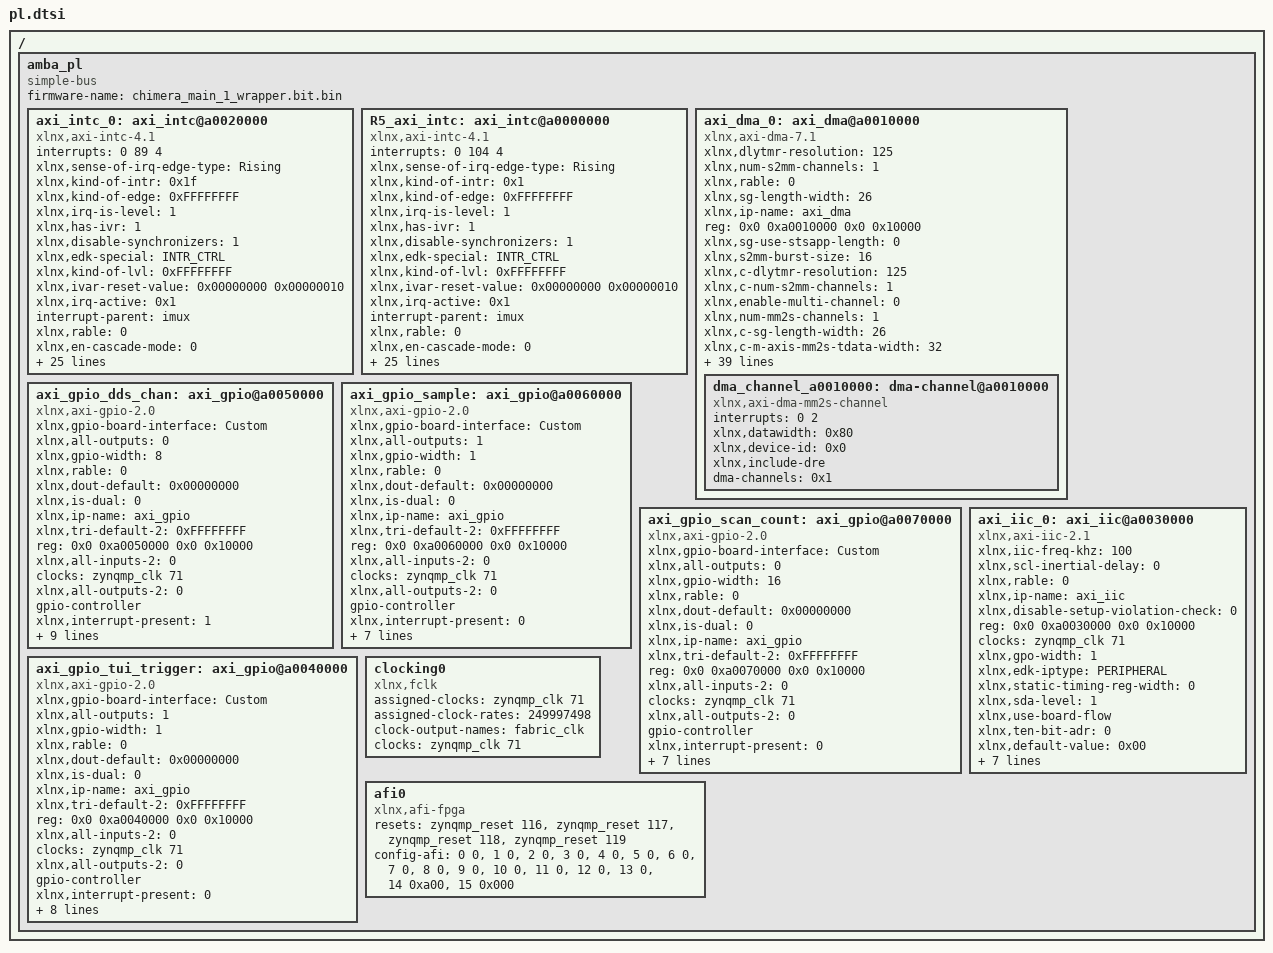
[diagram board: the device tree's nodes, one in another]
/ {
	amba_pl: amba_pl {
		ranges;
		compatible = "simple-bus";
		#address-cells = <2>;
		#size-cells = <2>;
		firmware-name = "chimera_main_1_wrapper.bit.bin";
		axi_intc_0: axi_intc@a0020000 {
			#interrupt-cells = <2>;
			interrupts = < 0 89 4 >;
			xlnx,sense-of-irq-edge-type = "Rising";
			xlnx,kind-of-intr = <0x1f>;
			xlnx,kind-of-edge = <0xFFFFFFFF>;
			xlnx,irq-is-level = <1>;
			xlnx,has-ivr = <1>;
			compatible = "xlnx,axi-intc-4.1" , "xlnx,xps-intc-1.00.a";
			xlnx,disable-synchronizers = <1>;
			xlnx,edk-special = "INTR_CTRL";
			xlnx,kind-of-lvl = <0xFFFFFFFF>;
			xlnx,ivar-reset-value = <0x00000000 0x00000010>;
			xlnx,irq-active = <0x1>;
			interrupt-parent = <&imux>;
			xlnx,rable = <0>;
			xlnx,en-cascade-mode = <0>;
			xlnx,ip-name = "axi_intc";
			xlnx,has-ilr = <0>;
			reg = <0x0 0xa0020000 0x0 0x10000>;
			xlnx,addr-width = <0x20>;
			clocks = <&zynqmp_clk 71>;
			xlnx,s-axi-aclk-freq-mhz = <0xee6a8ba>;
			xlnx,num-sw-intr = <0>;
			xlnx,irq-connection = <1>;
			xlnx,num-intr-inputs = <0x5>;
			xlnx,has-sie = <1>;
			xlnx,has-cie = <1>;
			xlnx,enable-async = <0>;
			xlnx,num-sync-ff = <2>;
			xlnx,mb-clk-not-connected = <1>;
			xlnx,has-ipr = <1>;
			xlnx,edk-iptype = "PERIPHERAL";
			xlnx,sense-of-irq-level-type = "Active_High";
			xlnx,cascade-master = <0>;
			xlnx,processor-clk-freq-mhz = <250>;
			status = "okay";
			xlnx,is-fast = <0x0>;
			clock-names = "s_axi_aclk";
			xlnx,has-fast = <0>;
			xlnx,ivar-rst-val = <0x0000000000000010>;
			interrupt-controller;
			interrupt-names = "irq";
			xlnx,async-intr = <0xFFFFFFE0>;
			xlnx,name = "axi_intc_0";
		};
		R5_axi_intc: axi_intc@a0000000 {
			#interrupt-cells = <2>;
			interrupts = < 0 104 4 >;
			xlnx,sense-of-irq-edge-type = "Rising";
			xlnx,kind-of-intr = <0x1>;
			xlnx,kind-of-edge = <0xFFFFFFFF>;
			xlnx,irq-is-level = <1>;
			xlnx,has-ivr = <1>;
			compatible = "xlnx,axi-intc-4.1" , "xlnx,xps-intc-1.00.a";
			xlnx,disable-synchronizers = <1>;
			xlnx,edk-special = "INTR_CTRL";
			xlnx,kind-of-lvl = <0xFFFFFFFF>;
			xlnx,ivar-reset-value = <0x00000000 0x00000010>;
			xlnx,irq-active = <0x1>;
			interrupt-parent = <&imux>;
			xlnx,rable = <0>;
			xlnx,en-cascade-mode = <0>;
			xlnx,ip-name = "axi_intc";
			xlnx,has-ilr = <0>;
			reg = <0x0 0xa0000000 0x0 0x10000>;
			xlnx,addr-width = <0x20>;
			clocks = <&zynqmp_clk 71>;
			xlnx,s-axi-aclk-freq-mhz = <0xee6a8ba>;
			xlnx,num-sw-intr = <0>;
			xlnx,irq-connection = <1>;
			xlnx,num-intr-inputs = <0x1>;
			xlnx,has-sie = <1>;
			xlnx,has-cie = <1>;
			xlnx,enable-async = <0>;
			xlnx,num-sync-ff = <2>;
			xlnx,mb-clk-not-connected = <1>;
			xlnx,has-ipr = <1>;
			xlnx,edk-iptype = "PERIPHERAL";
			xlnx,sense-of-irq-level-type = "Active_High";
			xlnx,cascade-master = <0>;
			xlnx,processor-clk-freq-mhz = <250>;
			status = "okay";
			xlnx,is-fast = <0x0>;
			clock-names = "s_axi_aclk";
			xlnx,has-fast = <0>;
			xlnx,ivar-rst-val = <0x0000000000000010>;
			interrupt-controller;
			interrupt-names = "irq";
			xlnx,async-intr = <0xFFFFFFFF>;
			xlnx,name = "R5_axi_intc";
		};
		axi_dma_0: axi_dma@a0010000 {
			xlnx,dlytmr-resolution = <125>;
			xlnx,num-s2mm-channels = <1>;
			xlnx,rable = <0>;
			xlnx,sg-length-width = <26>;
			xlnx,ip-name = "axi_dma";
			reg = <0x0 0xa0010000 0x0 0x10000>;
			xlnx,sg-use-stsapp-length = <0>;
			xlnx,s2mm-burst-size = <16>;
			xlnx,c-dlytmr-resolution = <125>;
			xlnx,c-num-s2mm-channels = <1>;
			xlnx,enable-multi-channel = <0>;
			xlnx,num-mm2s-channels = <1>;
			xlnx,c-sg-length-width = <26>;
			interrupt-names = "mm2s_introut";
			compatible = "xlnx,axi-dma-7.1" , "xlnx,axi-dma-1.00.a";
			xlnx,c-m-axis-mm2s-tdata-width = <32>;
			xlnx,c-sg-use-stsapp-length = <0>;
			xlnx,c-s2mm-burst-size = <16>;
			xlnx,mm2s-burst-size = <32>;
			xlnx,c-enable-multi-channel = <0>;
			xlnx,c-num-mm2s-channels = <1>;
			interrupt-parent = <&axi_intc_0>;
			xlnx,include-s2mm-dre = <0>;
			xlnx,c-mm2s-burst-size = <32>;
			status = "okay";
			xlnx,c-include-s2mm-dre = <0>;
			xlnx,include-mm2s-dre = <1>;
			xlnx,name = "axi_dma_0";
			interrupts = < 0 2 >;
			xlnx,c-include-sg = <0>;
			xlnx,c-m-axi-s2mm-data-width = <32>;
			xlnx,include-s2mm-sf = <1>;
			xlnx,c-include-mm2s-dre = <1>;
			xlnx,include-s2mm = <0>;
			clocks = <&zynqmp_clk 71>, <&zynqmp_clk 71>;
			xlnx,addrwidth = <0x20>;
			xlnx,c-m-axi-mm2s-data-width = <128>;
			xlnx,edk-iptype = "PERIPHERAL";
			xlnx,c-include-s2mm-sf = <1>;
			xlnx,include-mm2s-sf = <1>;
			clock-names = "m_axi_mm2s_aclk" , "s_axi_lite_aclk";
			xlnx,c-include-s2mm = <0>;
			xlnx,c-addr-width = <32>;
			xlnx,c-single-interface = <0>;
			xlnx,include-mm2s = <1>;
			xlnx,c-s-axis-s2mm-tdata-width = <32>;
			xlnx,s2mm-data-width = <0x20>;
			xlnx,c-include-mm2s-sf = <1>;
			xlnx,prmry-is-aclk-async = <0>;
			xlnx,c-include-mm2s = <1>;
			xlnx,increase-throughput = <0>;
			xlnx,micro-dma = <0>;
			xlnx,mm2s-data-width = <0x80>;
			xlnx,c-prmry-is-aclk-async = <0>;
			xlnx,c-sg-include-stscntrl-strm = <0>;
			xlnx,c-increase-throughput = <0>;
			xlnx,c-micro-dma = <0>;
			dma_channel_a0010000: dma-channel@a0010000 {
				interrupts = <0 2>;
				xlnx,datawidth = <0x80>;
				xlnx,device-id = <0x0>;
				compatible = "xlnx,axi-dma-mm2s-channel";
				xlnx,include-dre;
				dma-channels = <0x1>;
			};
		};
		axi_gpio_dds_chan: axi_gpio@a0050000 {
			#interrupt-cells = <2>;
			xlnx,gpio-board-interface = "Custom";
			compatible = "xlnx,axi-gpio-2.0" , "xlnx,xps-gpio-1.00.a";
			xlnx,all-outputs = <0>;
			#gpio-cells = <2>;
			xlnx,gpio-width = <8>;
			xlnx,rable = <0>;
			xlnx,dout-default = <0x00000000>;
			xlnx,is-dual = <0>;
			xlnx,ip-name = "axi_gpio";
			xlnx,tri-default-2 = <0xFFFFFFFF>;
			reg = <0x0 0xa0050000 0x0 0x10000>;
			xlnx,all-inputs-2 = <0>;
			clocks = <&zynqmp_clk 71>;
			xlnx,all-outputs-2 = <0>;
			gpio-controller;
			xlnx,interrupt-present = <1>;
			xlnx,gpio2-board-interface = "Custom";
			xlnx,edk-iptype = "PERIPHERAL";
			xlnx,dout-default-2 = <0x00000000>;
			xlnx,gpio2-width = <32>;
			status = "okay";
			clock-names = "s_axi_aclk";
			xlnx,use-board-flow;
			interrupt-controller;
			xlnx,tri-default = <0xFFFFFFFF>;
			xlnx,name = "axi_gpio_dds_chan";
			xlnx,all-inputs = <1>;
		};
		axi_gpio_sample: axi_gpio@a0060000 {
			xlnx,gpio-board-interface = "Custom";
			compatible = "xlnx,axi-gpio-2.0" , "xlnx,xps-gpio-1.00.a";
			xlnx,all-outputs = <1>;
			#gpio-cells = <2>;
			xlnx,gpio-width = <1>;
			xlnx,rable = <0>;
			xlnx,dout-default = <0x00000000>;
			xlnx,is-dual = <0>;
			xlnx,ip-name = "axi_gpio";
			xlnx,tri-default-2 = <0xFFFFFFFF>;
			reg = <0x0 0xa0060000 0x0 0x10000>;
			xlnx,all-inputs-2 = <0>;
			clocks = <&zynqmp_clk 71>;
			xlnx,all-outputs-2 = <0>;
			gpio-controller;
			xlnx,interrupt-present = <0>;
			xlnx,gpio2-board-interface = "Custom";
			xlnx,edk-iptype = "PERIPHERAL";
			xlnx,dout-default-2 = <0x00000000>;
			xlnx,gpio2-width = <32>;
			status = "okay";
			clock-names = "s_axi_aclk";
			xlnx,tri-default = <0xFFFFFFFF>;
			xlnx,name = "axi_gpio_sample";
			xlnx,all-inputs = <0>;
		};
		axi_gpio_scan_count: axi_gpio@a0070000 {
			xlnx,gpio-board-interface = "Custom";
			compatible = "xlnx,axi-gpio-2.0" , "xlnx,xps-gpio-1.00.a";
			xlnx,all-outputs = <0>;
			#gpio-cells = <2>;
			xlnx,gpio-width = <16>;
			xlnx,rable = <0>;
			xlnx,dout-default = <0x00000000>;
			xlnx,is-dual = <0>;
			xlnx,ip-name = "axi_gpio";
			xlnx,tri-default-2 = <0xFFFFFFFF>;
			reg = <0x0 0xa0070000 0x0 0x10000>;
			xlnx,all-inputs-2 = <0>;
			clocks = <&zynqmp_clk 71>;
			xlnx,all-outputs-2 = <0>;
			gpio-controller;
			xlnx,interrupt-present = <0>;
			xlnx,gpio2-board-interface = "Custom";
			xlnx,edk-iptype = "PERIPHERAL";
			xlnx,dout-default-2 = <0x00000000>;
			xlnx,gpio2-width = <32>;
			status = "okay";
			clock-names = "s_axi_aclk";
			xlnx,tri-default = <0xFFFFFFFF>;
			xlnx,name = "axi_gpio_scan_count";
			xlnx,all-inputs = <1>;
		};
		axi_gpio_tui_trigger: axi_gpio@a0040000 {
			xlnx,gpio-board-interface = "Custom";
			compatible = "xlnx,axi-gpio-2.0" , "xlnx,xps-gpio-1.00.a";
			xlnx,all-outputs = <1>;
			#gpio-cells = <2>;
			xlnx,gpio-width = <1>;
			xlnx,rable = <0>;
			xlnx,dout-default = <0x00000000>;
			xlnx,is-dual = <0>;
			xlnx,ip-name = "axi_gpio";
			xlnx,tri-default-2 = <0xFFFFFFFF>;
			reg = <0x0 0xa0040000 0x0 0x10000>;
			xlnx,all-inputs-2 = <0>;
			clocks = <&zynqmp_clk 71>;
			xlnx,all-outputs-2 = <0>;
			gpio-controller;
			xlnx,interrupt-present = <0>;
			xlnx,gpio2-board-interface = "Custom";
			xlnx,edk-iptype = "PERIPHERAL";
			xlnx,dout-default-2 = <0x00000000>;
			xlnx,gpio2-width = <32>;
			status = "okay";
			clock-names = "s_axi_aclk";
			xlnx,use-board-flow;
			xlnx,tri-default = <0xFFFFFFFF>;
			xlnx,name = "axi_gpio_tui_trigger";
			xlnx,all-inputs = <0>;
		};
		axi_iic_0: axi_iic@a0030000 {
			xlnx,iic-freq-khz = <100>;
			compatible = "xlnx,axi-iic-2.1" , "xlnx,xps-iic-2.00.a";
			xlnx,scl-inertial-delay = <0>;
			xlnx,rable = <0>;
			xlnx,ip-name = "axi_iic";
			xlnx,disable-setup-violation-check = <0>;
			reg = <0x0 0xa0030000 0x0 0x10000>;
			clocks = <&zynqmp_clk 71>;
			xlnx,gpo-width = <1>;
			xlnx,edk-iptype = "PERIPHERAL";
			xlnx,static-timing-reg-width = <0>;
			xlnx,sda-level = <1>;
			status = "okay";
			clock-names = "s_axi_aclk";
			xlnx,use-board-flow;
			xlnx,ten-bit-adr = <0>;
			xlnx,default-value = <0x00>;
			xlnx,timing-reg-width = <32>;
			xlnx,iic-board-interface = "Custom";
			xlnx,iic-freq = <100000>;
			xlnx,smbus-pmbus-host = <0>;
			xlnx,sda-inertial-delay = <0>;
			xlnx,name = "axi_iic_0";
			xlnx,axi-aclk-freq-mhz = <0xee6a8ba>;
		};
		clocking0: clocking0 {
			compatible = "xlnx,fclk";
			assigned-clocks = <&zynqmp_clk 71>;
			assigned-clock-rates = <249997498>;
			#clock-cells = <0>;
			clock-output-names = "fabric_clk";
			clocks = <&zynqmp_clk 71>;
		};
		afi0: afi0 {
			status = "okay";
			compatible = "xlnx,afi-fpga";
			resets = <&zynqmp_reset 116>, <&zynqmp_reset 117>, <&zynqmp_reset 118>, <&zynqmp_reset 119>;
			config-afi = < 0 0>, <1 0>, <2 0>, <3 0>, <4 0>, <5 0>, <6 0>, <7 0>, <8 0>, <9 0>, <10 0>, <11 0>, <12 0>, <13 0>, <14 0xa00>, <15 0x000>;
		};
	};
};
